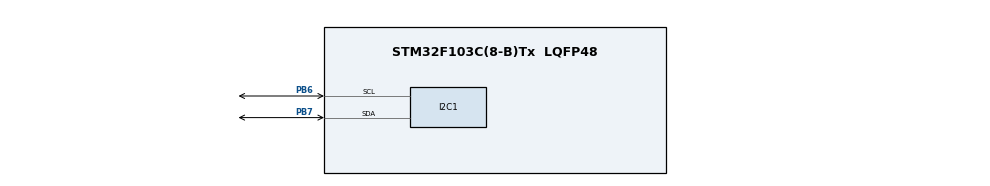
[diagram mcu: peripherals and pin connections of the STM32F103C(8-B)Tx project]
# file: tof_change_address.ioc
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I2C1.I2C_Mode=I2C_Fast
Mcu.Family=STM32F1
Mcu.Name=STM32F103C(8-B)Tx
Mcu.Package=LQFP48
NVIC.PriorityGroup=NVIC_PRIORITYGROUP_4
PA13.Mode=Serial_Wire
PA13.Signal=SYS_JTMS-SWDIO
PA14.Mode=Serial_Wire
PA14.Signal=SYS_JTCK-SWCLK
PB6.Mode=I2C
PB6.Signal=I2C1_SCL
PB7.Mode=I2C
PB7.Signal=I2C1_SDA
ProjectManager.HeapSize=0x200
ProjectManager.StackSize=0x400
ProjectManager.TargetToolchain=STM32CubeIDE
RCC.APB1Freq_Value=8000000
RCC.APB2Freq_Value=8000000
board=custom

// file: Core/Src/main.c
/* USER CODE BEGIN Header */
/**
  ******************************************************************************
  * @file           : main.c
  * @brief          : Main program body
  ******************************************************************************
  * @attention
  *
  * Copyright (c) 2025 STMicroelectronics.
  * All rights reserved.
  *
  * This software is licensed under terms that can be found in the LICENSE file
  * in the root directory of this software component.
  * If no LICENSE file comes with this software, it is provided AS-IS.
  *
  ******************************************************************************
  */
/* USER CODE END Header */
#include "main.h"

/* USER CODE BEGIN Includes */
#include "VL53L0X.h"
#include <stdio.h>
#include "fonts.h"
#include "ssd1306.h"
/* USER CODE END Includes */

I2C_HandleTypeDef hi2c1;

void SystemClock_Config(void);
static void MX_GPIO_Init(void);
static void MX_I2C1_Init(void);

/* USER CODE BEGIN 0 */
uint8_t stop_variable = 50;
uint16_t timeout_start_ms = 50;
uint16_t io_timeout = 50;
uint8_t did_timeout = 50;

void writeRegnew(uint8_t deviceAddress, uint8_t reg, uint8_t value)
{
    uint8_t array[2];
    array[0] = reg;    // Register address
    array[1] = value;  // Value to write
    HAL_I2C_Master_Transmit(&hi2c1, (deviceAddress << 1), array, 2, HAL_MAX_DELAY);
}

void scanI2CBus(void) {
    char buffer[16];
    SSD1306_Clear();
    SSD1306_GotoXY(0, 0);
    SSD1306_Puts("I2C Scan:", &Font_11x18, 1);

    for (uint8_t address = 1; address < 128; address++) {
        // Perform an I2C write operation to check if the device responds
        if (HAL_I2C_IsDeviceReady(&hi2c1, (address << 1), 1, 10) == HAL_OK) {
            snprintf(buffer, sizeof(buffer), "Found: 0x%02X", address);
            SSD1306_GotoXY(0, 30);
            SSD1306_Puts(buffer, &Font_11x18, 1);
            SSD1306_UpdateScreen();
            HAL_Delay(1000);
            //SD1306_Clear();// Delay to display each address found
        }
    }
    HAL_Delay(2000);  // Delay at the end of the scan
}
/* USER CODE END 0 */

int main(void)
{

  /* MCU Configuration--------------------------------------------------------*/

  /* Reset of all peripherals, Initializes the Flash interface and the Systick. */
  HAL_Init();

  /* USER CODE BEGIN Init */
  SSD1306_Init();
  SSD1306_GotoXY(0, 30);
  SSD1306_Puts("Initializing", &Font_11x18, 1);
  SSD1306_UpdateScreen();
  HAL_Delay(500);

  if (HAL_I2C_Init(&hi2c1) != HAL_OK) {
      SSD1306_GotoXY(0, 30);
      SSD1306_Puts("Failed", &Font_11x18, 1);
      SSD1306_UpdateScreen();
      HAL_Delay(2000);
      Error_Handler();
  } else {
      SSD1306_GotoXY(0, 30);
      SSD1306_Puts("Success", &Font_11x18, 1);
      HAL_Delay(2000);
      SSD1306_UpdateScreen();
  }

  if (!init(true)) {
      SSD1306_GotoXY(0, 30);
      SSD1306_Puts("Failed2", &Font_11x18, 1);
      SSD1306_UpdateScreen();
      HAL_Delay(2000);
      Error_Handler();  // Will halt the program here
  }
  //setAddress(0x31);
  uint8_t currentAddress = 0x29;  // Default address
  uint8_t newAddress = 0x31;      // New desired address
  writeRegnew(currentAddress, 0x8A, newAddress & 0x7F);  // Change address
  //I2C_SLAVE_DEVICE_ADDRESS = newAddress;

  HAL_Delay(10);

  SSD1306_GotoXY(0, 30);
  SSD1306_Puts("Initialized", &Font_11x18, 1);
  SSD1306_UpdateScreen();
  HAL_Delay(1000);
  SSD1306_Clear();

  scanI2CBus();
  SSD1306_Clear();

  uint16_t distance;
  char buffer[16];
  /* USER CODE END Init */

  /* Configure the system clock */
  SystemClock_Config();

  /* Initialize all configured peripherals */
  MX_GPIO_Init();
  MX_I2C1_Init();

  /* Infinite loop */
  while (1)
  {

  }
}

void SystemClock_Config(void)
{
  RCC_OscInitTypeDef RCC_OscInitStruct = {0};
  RCC_ClkInitTypeDef RCC_ClkInitStruct = {0};

  /** Initializes the RCC Oscillators according to the specified parameters
  * in the RCC_OscInitTypeDef structure.
  */
  RCC_OscInitStruct.OscillatorType = RCC_OSCILLATORTYPE_HSI;
  RCC_OscInitStruct.HSIState = RCC_HSI_ON;
  RCC_OscInitStruct.HSICalibrationValue = RCC_HSICALIBRATION_DEFAULT;
  RCC_OscInitStruct.PLL.PLLState = RCC_PLL_NONE;
  if (HAL_RCC_OscConfig(&RCC_OscInitStruct) != HAL_OK)
  {
    Error_Handler();
  }

  /** Initializes the CPU, AHB and APB buses clocks
  */
  RCC_ClkInitStruct.ClockType = RCC_CLOCKTYPE_HCLK|RCC_CLOCKTYPE_SYSCLK
                              |RCC_CLOCKTYPE_PCLK1|RCC_CLOCKTYPE_PCLK2;
  RCC_ClkInitStruct.SYSCLKSource = RCC_SYSCLKSOURCE_HSI;
  RCC_ClkInitStruct.AHBCLKDivider = RCC_SYSCLK_DIV1;
  RCC_ClkInitStruct.APB1CLKDivider = RCC_HCLK_DIV1;
  RCC_ClkInitStruct.APB2CLKDivider = RCC_HCLK_DIV1;

  if (HAL_RCC_ClockConfig(&RCC_ClkInitStruct, FLASH_LATENCY_0) != HAL_OK)
  {
    Error_Handler();
  }
}

static void MX_I2C1_Init(void)
{

  hi2c1.Instance = I2C1;
  hi2c1.Init.ClockSpeed = 400000;
  hi2c1.Init.DutyCycle = I2C_DUTYCYCLE_2;
  hi2c1.Init.OwnAddress1 = 0;
  hi2c1.Init.AddressingMode = I2C_ADDRESSINGMODE_7BIT;
  hi2c1.Init.DualAddressMode = I2C_DUALADDRESS_DISABLE;
  hi2c1.Init.OwnAddress2 = 0;
  hi2c1.Init.GeneralCallMode = I2C_GENERALCALL_DISABLE;
  hi2c1.Init.NoStretchMode = I2C_NOSTRETCH_DISABLE;
  if (HAL_I2C_Init(&hi2c1) != HAL_OK)
  {
    Error_Handler();
  }

}

static void MX_GPIO_Init(void)
{

  /* GPIO Ports Clock Enable */
  __HAL_RCC_GPIOA_CLK_ENABLE();
  __HAL_RCC_GPIOB_CLK_ENABLE();

}

void Error_Handler(void)
{
  __disable_irq();
  while (1)
  {
  }
}
